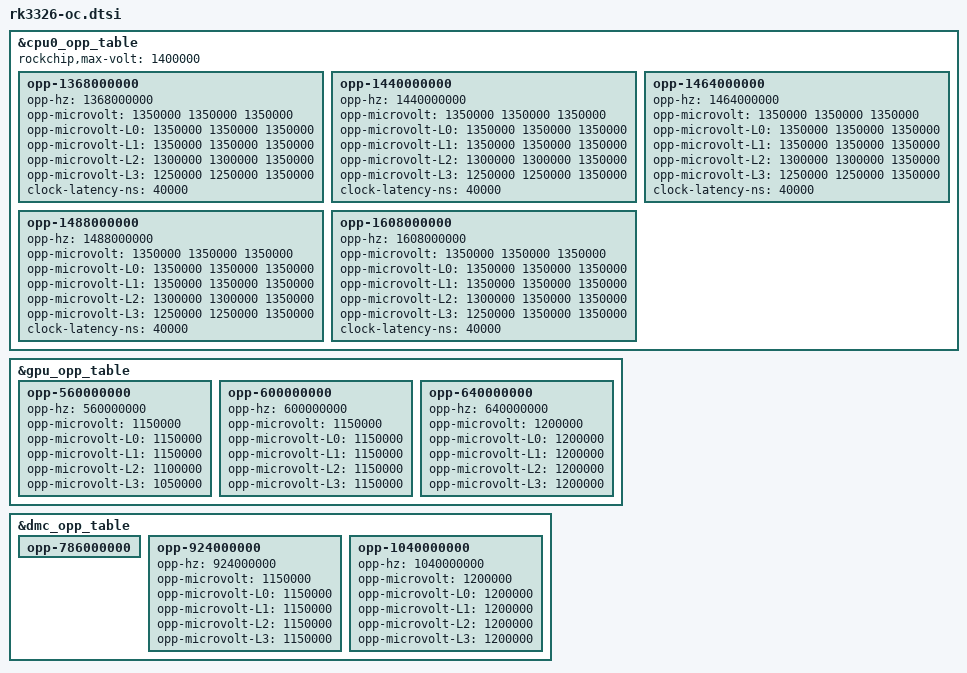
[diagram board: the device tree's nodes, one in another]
/*
* Copyright (c) 2017 Fuzhou Rockchip Electronics Co., Ltd
*
* SPDX-License-Identifier: (GPL-2.0+ OR MIT)
*/

#include "px30.dtsi"

&cpu0_opp_table {
	rockchip,max-volt = <1400000>;
	
	opp-1368000000 {
		opp-hz = /bits/ 64 <1368000000>;
		opp-microvolt = <1350000 1350000 1350000>;
		opp-microvolt-L0 = <1350000 1350000 1350000>;
		opp-microvolt-L1 = <1350000 1350000 1350000>;
		opp-microvolt-L2 = <1300000 1300000 1350000>;
		opp-microvolt-L3 = <1250000 1250000 1350000>;
		clock-latency-ns = <40000>;
	};
	opp-1440000000 {
		opp-hz = /bits/ 64 <1440000000>;
		opp-microvolt = <1350000 1350000 1350000>;
		opp-microvolt-L0 = <1350000 1350000 1350000>;
		opp-microvolt-L1 = <1350000 1350000 1350000>;
		opp-microvolt-L2 = <1300000 1300000 1350000>;
		opp-microvolt-L3 = <1250000 1250000 1350000>;
		clock-latency-ns = <40000>;
	};
	opp-1464000000 {
		opp-hz = /bits/ 64 <1464000000>;
		opp-microvolt = <1350000 1350000 1350000>;
		opp-microvolt-L0 = <1350000 1350000 1350000>;
		opp-microvolt-L1 = <1350000 1350000 1350000>;
		opp-microvolt-L2 = <1300000 1300000 1350000>;
		opp-microvolt-L3 = <1250000 1250000 1350000>;
		clock-latency-ns = <40000>;
	};
	opp-1488000000 {
		opp-hz = /bits/ 64 <1488000000>;
		opp-microvolt = <1350000 1350000 1350000>;
		opp-microvolt-L0 = <1350000 1350000 1350000>;
		opp-microvolt-L1 = <1350000 1350000 1350000>;
		opp-microvolt-L2 = <1300000 1300000 1350000>;
		opp-microvolt-L3 = <1250000 1250000 1350000>;
		clock-latency-ns = <40000>;
	};
	opp-1608000000 {
		opp-hz = /bits/ 64 <1608000000>;
		opp-microvolt = <1350000 1350000 1350000>;
		opp-microvolt-L0 = <1350000 1350000 1350000>;
		opp-microvolt-L1 = <1350000 1350000 1350000>;
		opp-microvolt-L2 = <1300000 1350000 1350000>;
		opp-microvolt-L3 = <1250000 1350000 1350000>;
		clock-latency-ns = <40000>;
	};
};

&gpu_opp_table {
	opp-560000000 {
		opp-hz = /bits/ 64 <560000000>;
		opp-microvolt = <1150000>;
		opp-microvolt-L0 = <1150000>;
		opp-microvolt-L1 = <1150000>;
		opp-microvolt-L2 = <1100000>;
		opp-microvolt-L3 = <1050000>;
	};
	opp-600000000 {
		opp-hz = /bits/ 64 <600000000>;
		opp-microvolt = <1150000>;
		opp-microvolt-L0 = <1150000>;
		opp-microvolt-L1 = <1150000>;
		opp-microvolt-L2 = <1150000>;
		opp-microvolt-L3 = <1150000>;
	};
	opp-640000000 {
		opp-hz = /bits/ 64 <640000000>;
		opp-microvolt = <1200000>;
		opp-microvolt-L0 = <1200000>;
		opp-microvolt-L1 = <1200000>;
		opp-microvolt-L2 = <1200000>;
		opp-microvolt-L3 = <1200000>;
	};
};

&dmc_opp_table {
	opp-786000000 {
		status = "okay";
	};
	opp-924000000 {
		opp-hz = /bits/ 64 <924000000>;
		opp-microvolt = <1150000>;
		opp-microvolt-L0 = <1150000>;
		opp-microvolt-L1 = <1150000>;
		opp-microvolt-L2 = <1150000>;
		opp-microvolt-L3 = <1150000>;
	};
	opp-1040000000 {
		opp-hz = /bits/ 64 <1040000000>;
		opp-microvolt = <1200000>;
		opp-microvolt-L0 = <1200000>;
		opp-microvolt-L1 = <1200000>;
		opp-microvolt-L2 = <1200000>;
		opp-microvolt-L3 = <1200000>;
	};
};
